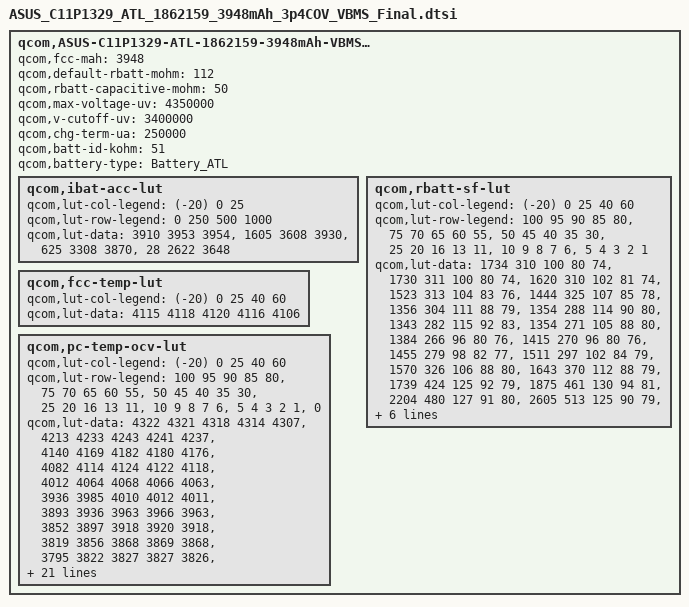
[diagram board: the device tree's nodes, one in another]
 qcom,ASUS-C11P1329-ATL-1862159-3948mAh-VBMS-data {
	qcom,fcc-mah = <3948>;
	qcom,default-rbatt-mohm = <112>;
	qcom,rbatt-capacitive-mohm = <50>;
	qcom,max-voltage-uv = <4350000>;
	qcom,v-cutoff-uv = <3400000>;
	qcom,chg-term-ua = <250000>;
	qcom,batt-id-kohm = <51>;
	qcom,battery-type = "Battery_ATL";

	qcom,ibat-acc-lut {
		qcom,lut-col-legend = <(-20) 0 25>;
		qcom,lut-row-legend = <0 250 500 1000>;
		qcom,lut-data = <3910 3953 3954>,
				<1605 3608 3930>,
				<625 3308 3870>,
				<28 2622 3648>;
	};

	qcom,rbatt-sf-lut {
		qcom,lut-col-legend = <(-20) 0 25 40 60>;
		qcom,lut-row-legend = <100 95 90 85 80>,
				<75 70 65 60 55>,
				<50 45 40 35 30>,
				<25 20 16 13 11>,
				<10 9 8 7 6>,
				<5 4 3 2 1>;
		qcom,lut-data = <1734 310 100 80 74>,
				<1730 311 100 80 74>,
				<1620 310 102 81 74>,
				<1523 313 104 83 76>,
				<1444 325 107 85 78>,
				<1356 304 111 88 79>,
				<1354 288 114 90 80>,
				<1343 282 115 92 83>,
				<1354 271 105 88 80>,
				<1384 266 96 80 76>,
				<1415 270 96 80 76>,
				<1455 279 98 82 77>,
				<1511 297 102 84 79>,
				<1570 326 106 88 80>,
				<1643 370 112 88 79>,
				<1739 424 125 92 79>,
				<1875 461 130 94 81>,
				<2204 480 127 91 80>,
				<2605 513 125 90 79>,
				<3454 560 128 90 79>,
				<4205 595 129 92 80>,
				<5321 639 134 94 80>,
				<6849 704 138 96 82>,
				<9142 796 145 97 82>,
				<12588 934 152 99 82>,
				<17362 1186 155 98 80>,
				<24452 1643 159 98 82>,
				<33280 2476 172 103 84>,
				<47262 3736 197 109 86>,
				<68198 5391 245 121 91>;
	};

	qcom,fcc-temp-lut {
		qcom,lut-col-legend = <(-20) 0 25 40 60>;
		qcom,lut-data = <4115 4118 4120 4116 4106>;
	};

	qcom,pc-temp-ocv-lut {
		qcom,lut-col-legend = <(-20) 0 25 40 60>;
		qcom,lut-row-legend = <100 95 90 85 80>,
				<75 70 65 60 55>,
				<50 45 40 35 30>,
				<25 20 16 13 11>,
				<10 9 8 7 6>,
				<5 4 3 2 1>,
				<0>;
		qcom,lut-data = <4322 4321 4318 4314 4307>,
				<4213 4233 4243 4241 4237>,
				<4140 4169 4182 4180 4176>,
				<4082 4114 4124 4122 4118>,
				<4012 4064 4068 4066 4063>,
				<3936 3985 4010 4012 4011>,
				<3893 3936 3963 3966 3963>,
				<3852 3897 3918 3920 3918>,
				<3819 3856 3868 3869 3868>,
				<3795 3822 3827 3827 3826>,
				<3774 3798 3801 3800 3799>,
				<3754 3783 3784 3782 3780>,
				<3734 3774 3775 3772 3768>,
				<3711 3766 3770 3767 3760>,
				<3686 3752 3762 3756 3745>,
				<3656 3722 3738 3734 3722>,
				<3622 3654 3672 3672 3668>,
				<3588 3586 3599 3601 3598>,
				<3554 3544 3554 3556 3554>,
				<3524 3521 3532 3536 3536>,
				<3506 3511 3524 3528 3528>,
				<3488 3502 3516 3521 3520>,
				<3467 3492 3509 3513 3512>,
				<3448 3482 3500 3504 3503>,
				<3424 3470 3488 3491 3488>,
				<3400 3451 3466 3467 3458>,
				<3370 3419 3426 3423 3412>,
				<3327 3369 3368 3368 3355>,
				<3264 3296 3296 3293 3282>,
				<3164 3198 3195 3192 3183>,
				<3000 3000 3000 3000 3000>;
	};
};
